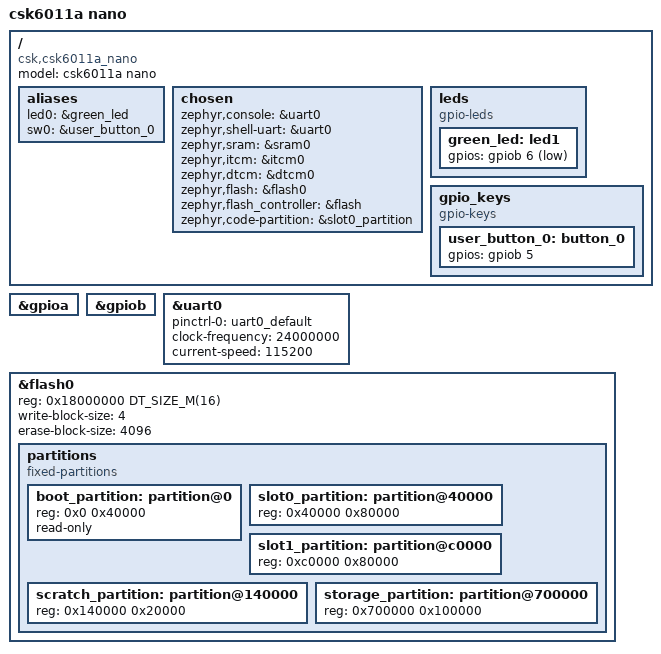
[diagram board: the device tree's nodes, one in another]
/* SPDX-License-Identifier: Apache-2.0 */

/dts-v1/;
#include <listenai/csk6/csk6.dtsi>
#include <zephyr/dt-bindings/pwm/pwm.h>
#include <zephyr/dt-bindings/gpio/gpio.h>
#include "csk6011a_nano_pinctrl.dtsi"

/ {
        model = "csk6011a nano";
        compatible = "csk,csk6011a_nano";
        aliases {
                led0 = &green_led;
                sw0 = &user_button_0;
        };

        chosen {
                zephyr,console = &uart0;
                zephyr,shell-uart = &uart0;
                zephyr,sram = &sram0;
                zephyr,itcm = &itcm0;
                zephyr,dtcm = &dtcm0;
                zephyr,flash = &flash0;
                zephyr,flash_controller = &flash;
                zephyr,code-partition = &slot0_partition;
        };

        leds {
                compatible = "gpio-leds";
                green_led: led1 {
                        gpios = <&gpiob 6 GPIO_ACTIVE_LOW>;
                };
        };


        gpio_keys {
                compatible = "gpio-keys";
                user_button_0: button_0 {
                        gpios = <&gpiob 5 0>;
                };
        };
};



&gpioa {
        status = "okay";
};

&gpiob {
        status = "okay";
};

&uart0 {
        pinctrl-0 = <&uart0_default>;
        pinctrl-names = "default";
        clock-frequency = <24000000>;
        current-speed = <115200>;
        status = "okay";
};

&flash0 {
        reg = <0x18000000 DT_SIZE_M(16)>;
        write-block-size = <4>;
        erase-block-size = <4096>;
        partitions {
                compatible = "fixed-partitions";
                #address-cells = <1>;
                #size-cells = <1>;

                boot_partition: partition@0 {
                        reg = <0x0 0x40000>;
                        read-only;
                };

                slot0_partition: partition@40000 {
                        reg = <0x40000 0x80000>;
                };

                slot1_partition: partition@c0000 {
                        reg = <0xc0000 0x80000>;
                };

                scratch_partition: partition@140000 {
                        reg = <0x140000 0x20000>;
                };
                storage_partition: partition@700000 {
                        reg = <0x700000 0x100000>;
                };
        };
};
